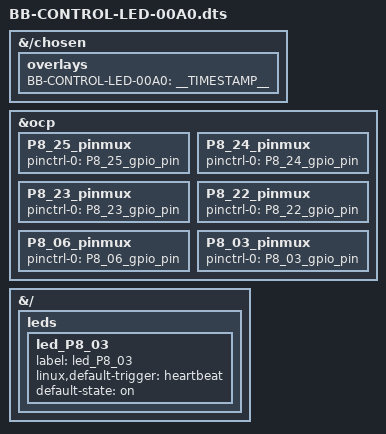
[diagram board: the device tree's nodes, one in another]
/*
 * Copyright (C) 2020 Robert Nelson <robertcnelson@gmail.com>
 *
 * This program is free software; you can redistribute it and/or modify
 * it under the terms of the GNU General Public License version 2 as
 * published by the Free Software Foundation.
 */

/dts-v1/;
/plugin/;

#include <dt-bindings/board/am335x-bbw-bbb-base.h>
#include <dt-bindings/gpio/gpio.h>
#include <dt-bindings/pinctrl/am33xx.h>


&{/chosen} {
        overlays {
                BB-CONTROL-LED-00A0 = __TIMESTAMP__;
        };
};
&ocp {
        P8_25_pinmux { pinctrl-0 = <&P8_25_gpio_pin>; };
        P8_24_pinmux { pinctrl-0 = <&P8_24_gpio_pin>; };
        P8_23_pinmux { pinctrl-0 = <&P8_23_gpio_pin>; };
        P8_22_pinmux { pinctrl-0 = <&P8_22_gpio_pin>; };
        P8_06_pinmux { pinctrl-0 = <&P8_06_gpio_pin>; };
        P8_03_pinmux { pinctrl-0 = <&P8_03_gpio_pin>; };
};

&{/} {
	leds {
		led_P8_03 {
			status = "okay";
			label = "led_P8_03"; // sys/class/leds/<label>
			linux,default-trigger = "heartbeat";
			default-state = "on";
		};
	};
};

